# ATxmega192A3U device description
Architecture: AVR8_XMEGA; Family: AVR XMEGA
Registers are 8-bit, access not given, no defined reset value unless marked. A register's access mark holds for its fields unless they carry their own. Offsets are from the block's base; [hi:lo] are bit positions; lines under a group give offsets from that group; {n}, {i} and the like mark numbered series; 'fields as' and 'values as' point back to an identical list.

## DAC — Digital-to-Analog Converter
Instances: DACB 0x0320
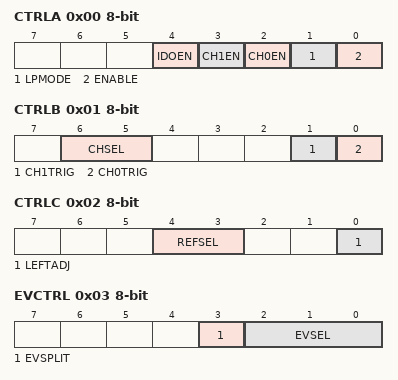
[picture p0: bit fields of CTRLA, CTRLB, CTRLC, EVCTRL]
0x00 CTRLA — Control Register A
  [4] IDOEN — Internal Output Enable
  [3] CH1EN — Channel 1 Output Enable
  [2] CH0EN — Channel 0 Output Enable
  [1] LPMODE — Low Power Mode
  [0] ENABLE
0x01 CTRLB — Control Register B
  [6:5] CHSEL — Channel Select
    0=SINGLE (Single channel operation (Channel 0 only)); 1=SINGLE1 (Single channel operation (Channel 1 only)); 2=DUAL (Dual channel operation (Channel 0 and channel 1))
  [1] CH1TRIG — Channel 1 Event Trig Enable
  [0] CH0TRIG — Channel 0 Event Trig Enable
0x02 CTRLC — Control Register C
  [4:3] REFSEL — Reference Select
    0=INT1V (Internal 1V); 1=AVCC (Analog supply voltage); 2=AREFA (External reference on AREF on PORTA); 3=AREFB (External reference on AREF on PORTB)
  [0] LEFTADJ — Left-adjust Result
0x03 EVCTRL — Event Input Control
  [3] EVSPLIT — Separate Event Channel Input for Channel 1
  [2:0] EVSEL — Event Input Selection
    {v}=Event Channel {v} (v=0..7)
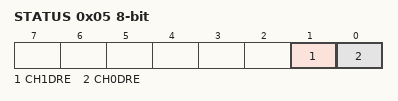
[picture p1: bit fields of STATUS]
0x05 STATUS
  [1] CH1DRE — Channel 1 Data Register Empty
  [0] CH0DRE — Channel 0 Data Register Empty
0x08 CH0GAINCAL — Gain Calibration
  [6:0] CH0GAINCAL
0x09 CH0OFFSETCAL — Offset Calibration
  [6:0] CH0OFFSETCAL
0x0A CH1GAINCAL — Gain Calibration
  [6:0] CH1GAINCAL
0x0B CH1OFFSETCAL — Offset Calibration
  [6:0] CH1OFFSETCAL
0x18 CH0DATA 16-bit — Channel 0 Data
0x1A CH1DATA 16-bit — Channel 1 Data

## RTC — Real-Time Counter
Instances: RTC 0x0400
0x00 CTRL — Control Register
  [2:0] PRESCALER — Prescaling Factor
    0=OFF (RTC Off); 1=DIV1 (RTC Clock); 2=DIV2 (RTC Clock / 2); 3=DIV8 (RTC Clock / 8); 4=DIV16 (RTC Clock / 16); 5=DIV64 (RTC Clock / 64); 6=DIV256 (RTC Clock / 256); 7=DIV1024 (RTC Clock / 1024)
0x01 STATUS
  [0] SYNCBUSY — Synchronization Busy Flag
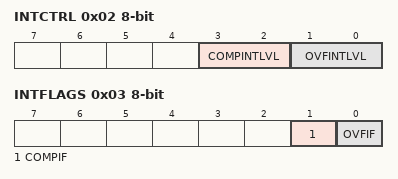
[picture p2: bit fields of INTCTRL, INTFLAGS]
0x02 INTCTRL — Interrupt Control Register
  [3:2] COMPINTLVL — Compare Match Interrupt Level
    0=OFF (Interrupt Disabled); 1=LO (Low Level); 2=MED (Medium Level); 3=HI (High Level)
  [1:0] OVFINTLVL — Overflow Interrupt Level
    values as COMPINTLVL
0x03 INTFLAGS — Interrupt Flags
  [1] COMPIF — Compare Match Interrupt Flag
  [0] OVFIF — Overflow Interrupt Flag
0x04 TEMP — Temporary register
0x08 CNT 16-bit — Count Register
0x0A PER 16-bit — Period Register
0x0C COMP 16-bit — Compare Register

## TWI — Two-Wire Interface
Instances: TWIC 0x480, TWIE 0x4A0
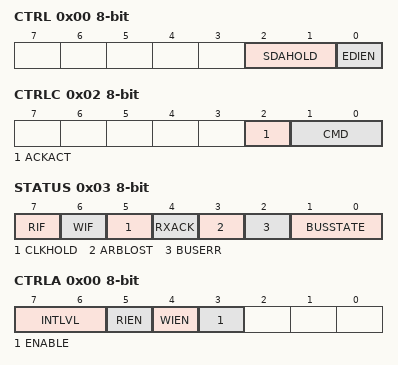
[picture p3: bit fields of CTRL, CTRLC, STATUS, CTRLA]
0x00 CTRL — TWI Common Control Register
  [2:1] SDAHOLD — SDA Hold Time Enable
    0=OFF (SDA Hold Time off); 1=50NS (SDA Hold Time 50 ns); 2=300NS (SDA Hold Time 300 ns); 3=400NS (SDA Hold Time 400 ns)
  [0] EDIEN — External Driver Interface Enable
0x01 MASTER group — TWI master module
  0x00 CTRLA — Control Register A
    [7:6] INTLVL — Interrupt Level
      0=OFF (Interrupt Disabled); 1=LO (Low Level); 2=MED (Medium Level); 3=HI (High Level)
    [5] RIEN — Read Interrupt Enable
    [4] WIEN — Write Interrupt Enable
    [3] ENABLE — Enable TWI Master
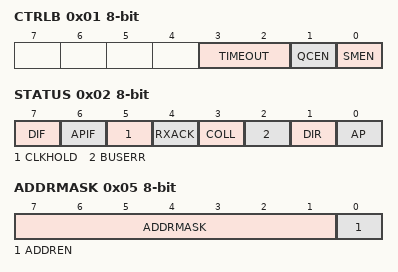
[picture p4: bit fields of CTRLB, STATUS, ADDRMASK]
  0x01 CTRLB — Control Register B
    [3:2] TIMEOUT — Inactive Bus Timeout
      0=DISABLED (Bus Timeout Disabled); 1=50US (50 Microseconds); 2=100US (100 Microseconds); 3=200US (200 Microseconds)
    [1] QCEN — Quick Command Enable
    [0] SMEN — Smart Mode Enable
  0x02 CTRLC — Control Register C
    [2] ACKACT — Acknowledge Action
    [1:0] CMD — Command
      0=NOACT (No Action); 1=REPSTART (Issue Repeated Start Condition); 2=RECVTRANS (Receive or Transmit Data); 3=STOP (Issue Stop Condition)
  0x03 STATUS
    [7] RIF — Read Interrupt Flag
    [6] WIF — Write Interrupt Flag
    [5] CLKHOLD — Clock Hold
    [4] RXACK — Received Acknowledge
    [3] ARBLOST — Arbitration Lost
    [2] BUSERR — Bus Error
    [1:0] BUSSTATE
      0=UNKNOWN (Unknown Bus State); 1=IDLE (Bus is Idle); 2=OWNER (This Module Controls The Bus); 3=BUSY (The Bus is Busy)
  0x04 BAUD — Baurd Rate Control Register
  0x05 ADDR — Address Register
  0x06 DATA
0x08 SLAVE group — TWI slave module
  0x00 CTRLA — Control Register A
    [7:6] INTLVL — Interrupt Level
      values as MASTER.CTRLA.INTLVL
    [5] DIEN — Data Interrupt Enable
    [4] APIEN — Address/Stop Interrupt Enable
    [3] ENABLE — Enable TWI Slave
    [2] PIEN — Stop Interrupt Enable
    [1] PMEN — Promiscuous Mode Enable
    [0] SMEN — Smart Mode Enable
  0x01 CTRLB — Control Register B
    [2] ACKACT — Acknowledge Action
    [1:0] CMD — Command
      0=NOACT (No Action); 2=COMPTRANS (Used To Complete a Transaction); 3=RESPONSE (Used in Response to Address/Data Interrupt)
  0x02 STATUS
    [7] DIF — Data Interrupt Flag
    [6] APIF — Address/Stop Interrupt Flag
    [5] CLKHOLD — Clock Hold
    [4] RXACK — Received Acknowledge
    [3] COLL — Collision
    [2] BUSERR — Bus Error
    [1] DIR — Read/Write Direction
    [0] AP — Slave Address or Stop
  0x03 ADDR — Address Register
  0x04 DATA
  0x05 ADDRMASK — Address Mask Register
    [7:1] ADDRMASK — Address Mask
    [0] ADDREN — Address Enable
